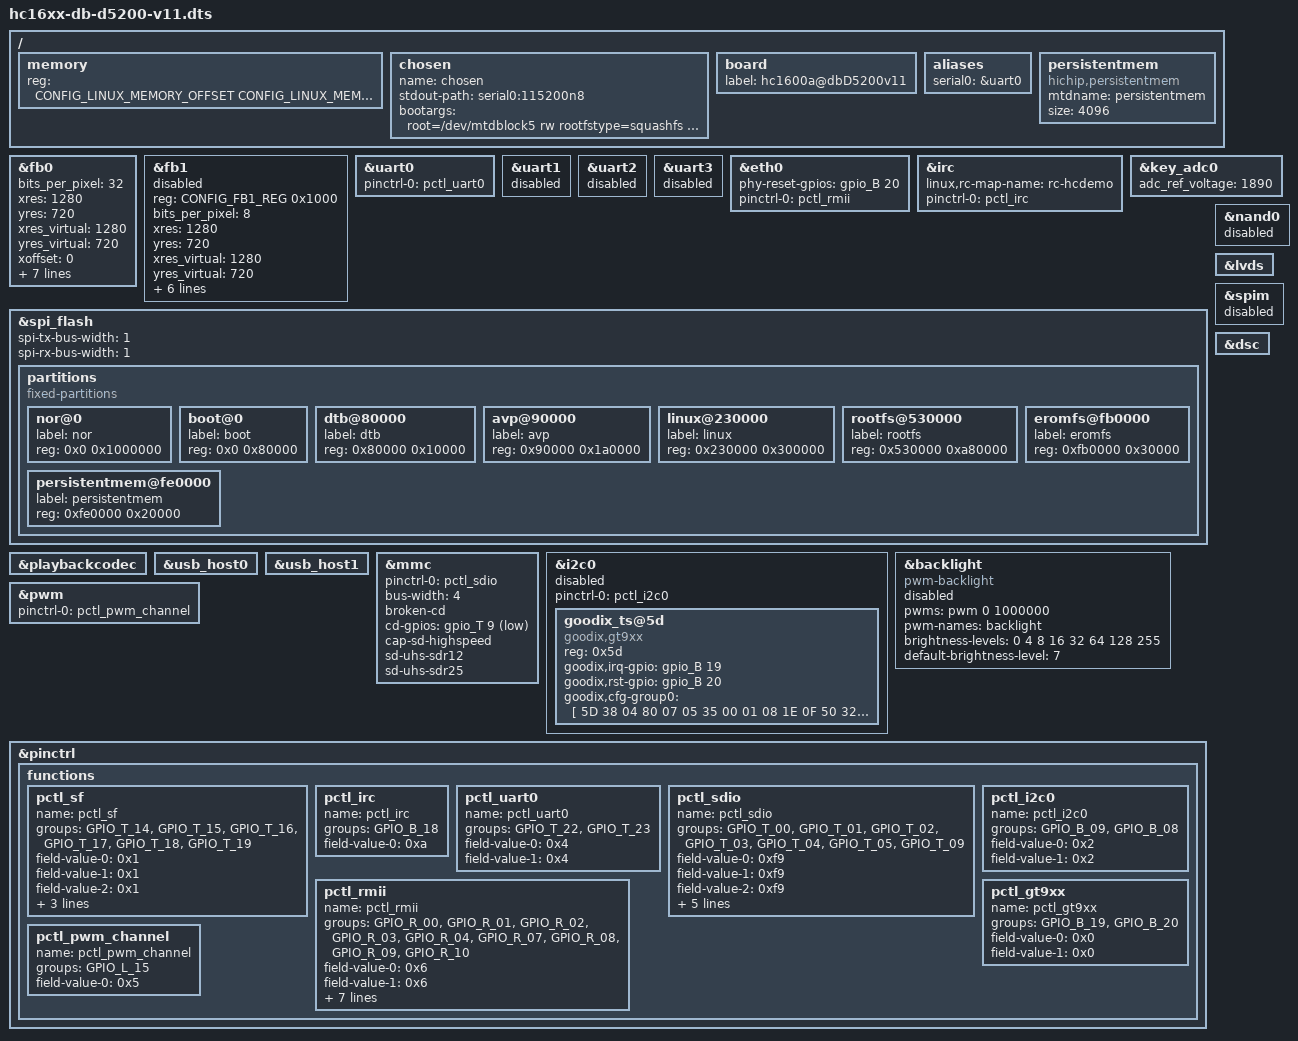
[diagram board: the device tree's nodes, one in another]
#include <uapi/hcuapi/pinpad.h>
#include "hc16xx-common.dtsi"
#include "hc16xx-db-d5200-v11-avp.dtsi"

#define CONFIG_AVP_MEMORY_SIZE (HCRTOS_SYSMEM_SIZE + HCRTOS_MMZ0_SIZE + HCRTOS_MMZ1_SIZE)
#define CONFIG_FRAMEBUFFER_STATIC_MEM_SIZE (0)
#define CONFIG_LINUX_MEMORY_SIZE (CONFIG_MEMORY_SIZE - CONFIG_AVP_MEMORY_SIZE - CONFIG_FRAMEBUFFER_STATIC_MEM_SIZE)
#define CONFIG_LINUX_MEMORY_OFFSET (0)
#define CONFIG_FRAMEBUFFER_STATIC_PHYS (CONFIG_LINUX_MEMORY_OFFSET + CONFIG_LINUX_MEMORY_SIZE)

/{
	#address-cells = <1>;
	#size-cells = <1>;
	memory {
		device_type = "memory";
		reg = <CONFIG_LINUX_MEMORY_OFFSET CONFIG_LINUX_MEMORY_SIZE>;
	};

	chosen: chosen {
		name = "chosen";
		stdout-path = "serial0:115200n8";
		bootargs = "root=/dev/mtdblock5 rw rootfstype=squashfs init=/linuxrc console=ttyS0,115200N8 earlycon=uart8250,mmio,0x18818300,115200n8 no_console_suspend noirqdebug";
		//bootargs = "root=/dev/ram0 rootfstype=ramfs rw init=/linuxrc console=ttyS0,115200N8 earlycon=uart8250,mmio,0x18818600,115200n8 no_console_suspend noirqdebug";
	};

	board {
		label = "hc1600a@dbD5200v11";
	};

	aliases {
		serial0 = &uart0;
	};

	persistentmem {
		compatible = "hichip,persistentmem";
		mtdname = "persistentmem";
		size = <4096>;
	};
};

&fb0 {
	bits_per_pixel = <32>;
	xres = <1280>;
	yres = <720>;
	xres_virtual = <1280>;
	yres_virtual = <720>;
	xoffset = <0>;
	yoffset = <0>;

	scale = <1280 720 1920 1080>;

	reg = <CONFIG_FB0_REG 0x1000>;
	/*
	 * frame buffer memory from:
	 * system : malloc buffer from system heap
	 * mmz0   : malloc buffer from mmz0
	 * static : use CONFIG_FRAMEBUFFER_STATIC_PHYS and CONFIG_FRAMEBUFFER_STATIC_MEM_SIZE to allocate memory staticly.
	 * default is system if the property is missing
	 */
	buffer-source = "system";
	extra-buffer-size = <0xC00000>; /* 8Mb */

	buffer-phy-static = <CONFIG_FRAMEBUFFER_STATIC_PHYS CONFIG_FRAMEBUFFER_STATIC_MEM_SIZE>;
	status = "okay";
};

&fb1 {
	reg = <CONFIG_FB1_REG 0x1000>;
	bits_per_pixel = <8>;
	xres = <1280>;
	yres = <720>;
	xres_virtual = <1280>;
	yres_virtual = <720>;
	xoffset = <0>;
	yoffset = <0>;

	scale = <1280 720 1920 1080>;
	/*
	 * frame buffer memory from:
	 * system : malloc buffer from system heap
	 * mmz0   : malloc buffer from mmz0
	 * default is system if the property is missing
	 */
	buffer-source = "system";
	extra-buffer-size = <0>; /* 8Mb */
	pre-multiply = <0>;
	status = "disabled";
};


&uart0 {
	pinctrl-names = "default";
	pinctrl-0 = <&pctl_uart0>;
	status = "okay";
};

&uart1 {
	status = "disabled";
};

&uart2 {
	status = "disabled";
};

&uart3 {
	status = "disabled";
};

&eth0 {
	phy-reset-gpios = <&gpio_B 20 0>;
	pinctrl-0 = <&pctl_rmii>;
	pinctrl-names = "active";
	status = "okay";
};

&irc {
	linux,rc-map-name = "rc-hcdemo";
	pinctrl-names = "active";
	pinctrl-0 = <&pctl_irc>;
	status = "okay";
};

&key_adc0 {
	status = "okay";
	adc_ref_voltage = <1890>; //range:0-2000mV
      /*key_map = <voltage_min, voltage_max, code>*/
};


&spi_flash {
	spi-tx-bus-width = <1>;
	spi-rx-bus-width = <1>;

	partitions {
		compatible = "fixed-partitions";
		#address-cells = <1>;
		#size-cells = <1>;

		nor@0 {
			label = "nor";
			reg = <0x0 0x1000000>;
		};

		boot@0 {
			label = "boot";
			reg = <0x0 0x80000>;
		};

		dtb@80000 {
			label = "dtb";
			reg = <0x80000 0x10000>;
		};

		avp@90000 {
			label = "avp";
			reg = <0x90000 0x1a0000>;
		};

		linux@230000 {
			label = "linux";
			reg = <0x230000 0x300000>;
		};

		rootfs@530000 {
			label = "rootfs";
			reg = <0x530000 0xa80000>;
		};

		eromfs@fb0000 {
			label = "eromfs";
			reg = <0xfb0000 0x30000>;
		};

		persistentmem@fe0000 {
			label = "persistentmem";
			reg = <0xfe0000 0x20000>;
		};
	};
};

&nand0 {
	status = "disabled";
};

&playbackcodec {
	//mute_gpio = <&gpio_T 30 0>;
};

&usb_host0 {
	status = "okay";
};

&usb_host1 {
	status = "okay";
};

&mmc {
	pinctrl-names = "default";
	pinctrl-0 = <&pctl_sdio>;   // pinctrl for SD
	status = "okay";

	// bus-width = <8>;
	bus-width = <4>;
	// bus-width = <1>;

	broken-cd;
	cd-gpios = <&gpio_T 9 GPIO_ACTIVE_LOW>;
	//non-removable;

	cap-sd-highspeed;
	sd-uhs-sdr12;
	sd-uhs-sdr25;
	//sd-uhs-ddr50;
	//sd-uhs-sdr50;
	//sd-uhs-sdr104;
};

&lvds {
	status = "okay";
};

&i2c0 {
	status = "disable";
	pinctrl-names = "active";
	pinctrl-0 = <&pctl_i2c0>;	

	goodix_ts@5d {
		compatible = "goodix,gt9xx";
		reg = <0x5d>;
		goodix,irq-gpio = <&gpio_B 19 GPIO_ACTIVE_HIGH>;   		// irq-pin
		/* check the eth0 node reset pin , to avoid multiplexing */
		goodix,rst-gpio = <&gpio_B 20 GPIO_ACTIVE_HIGH>;     	 //reset-pin
		// status = "okay"; 
		goodix,cfg-group0 = [		/* not required */
			5D 38 04 80 07 05 35 00 01 08
			1E 0F 50 32 03 05 00 00 00 00
			11 11 00 17 19 1C 14 89 29 0E
			50 52 0F 0A 00 00 00 9A 02 1C
			00 01 05 00 00 00 00 09 11 00
			00 3E 6C 8F F5 02 07 00 00 04
			D9 41 00 AE 49 00 8A 51 00 70
			5B 00 5C 66 00 5C 00 00 00 00
			F0 4A 3A FF FF 27 00 00 00 00
			00 00 00 00 00 00 00 00 00 00
			00 00 00 00 00 00 00 00 00 00
			00 00 1C 1A 18 16 14 12 10 0E
			0C 0A 08 06 04 02 00 00 00 00
			00 00 00 00 00 00 00 00 00 00
			00 00 00 02 04 06 08 0A 0F 10
			12 22 21 20 1F 1E 1D 1C 18 16
			FF FF FF FF FF FF FF FF 00 00
			00 00 00 00 00 00 00 00 00 00
			00 00 00 00 48 01];
	};
};

&backlight {
	compatible = "pwm-backlight";
	pwms = <&pwm 0  1000000>;
	pwm-names = "backlight";
	brightness-levels = <0 4 8 16 32 64 128 255>;
	default-brightness-level = <7>;
	status = "disabled";
};

&pwm {
	status = "okay";
	#pwm-cells = <2>;
	pinctrl-names = "active";
	pinctrl-0 = <&pctl_pwm_channel>;
};

&spim {
	status = "disabled";
};

&pinctrl {
	functions {
		pctl_sf: pctl_sf {
			name = "pctl_sf";
			groups = "GPIO_T_14", "GPIO_T_15", "GPIO_T_16", "GPIO_T_17", "GPIO_T_18", "GPIO_T_19";
			field-value-0 = <0x1>;
			field-value-1 = <0x1>;
			field-value-2 = <0x1>;
			field-value-3 = <0x1>;
			field-value-4 = <0x1>;
			field-value-5 = <0x1>;
		};

		pctl_irc: pctl_irc {
			name = "pctl_irc";
			groups = "GPIO_B_18";
			field-value-0 = <0xa>;
		};

		pctl_uart0: pctl_uart0 {
			name = "pctl_uart0";
			groups = "GPIO_T_22", "GPIO_T_23";
			field-value-0 = <0x4>;
			field-value-1 = <0x4>;
		};

		pctl_sdio: pctl_sdio {
			name = "pctl_sdio";
			groups = "GPIO_T_00", "GPIO_T_01", "GPIO_T_02", "GPIO_T_03",\
					"GPIO_T_04", "GPIO_T_05", "GPIO_T_09";
			field-value-0 = <0xf9>;
			field-value-1 = <0xf9>;
			field-value-2 = <0xf9>;
			field-value-3 = <0xf9>;
			field-value-4 = <0xf9>;
			field-value-5 = <0xf9>;
			field-value-6 = <0xf9>;
			field-value-7 = <0x00>;
		};

		pctl_rmii: pctl_rmii {
			name = "pctl_rmii";
			groups = "GPIO_R_00", "GPIO_R_01", "GPIO_R_02", "GPIO_R_03", "GPIO_R_04", "GPIO_R_07", "GPIO_R_08", "GPIO_R_09", "GPIO_R_10";
			field-value-0 = <0x6>;
			field-value-1 = <0x6>;
			field-value-2 = <0x6>;
			field-value-3 = <0x6>;
			field-value-4 = <0x6>;
			field-value-5 = <0x6>;
			field-value-6 = <0x6>;
			field-value-7 = <0x6>;
			field-value-8 = <0x6>;
		};

		pctl_i2c0: pctl_i2c0 {
			name = "pctl_i2c0";
			groups = "GPIO_B_09", "GPIO_B_08";
			field-value-0 = <0x2>;
			field-value-1 = <0x2>;
		};

		pctl_gt9xx: pctl_gt9xx{
				name = "pctl_gt9xx";
				groups = "GPIO_B_19","GPIO_B_20";
				field-value-0 = <0x0>;
				field-value-1 = <0x0>;
			};

		pctl_pwm_channel: pctl_pwm_channel {
			name = "pctl_pwm_channel";
			groups = "GPIO_L_15";
			field-value-0 = <0x5>;
		};

	};
};

&dsc {
	status = "okay";
};

// #include "lcd_mipi_1080_1920_rgb888_BOE497FHD.dtsi"
// #include "lcd_mipi_1920_1200_rgb888.dtsi"
#include "lcd_lvds_1024_600_vesa.dtsi"
